# PIC32CM2532LE00100 device description
Architecture: CORTEX-M23; Family: PIC32CM; Series: PIC32CMLE00
Registers are 32-bit, read-write, reset 0x0 unless marked. A register's access mark holds for its fields unless they carry their own. Offsets are from the block's base; [hi:lo] are bit positions; {n}, {i} and the like mark numbered series.

## MPU — Memory Protection Unit
Instances: MPU 0xE000ED90
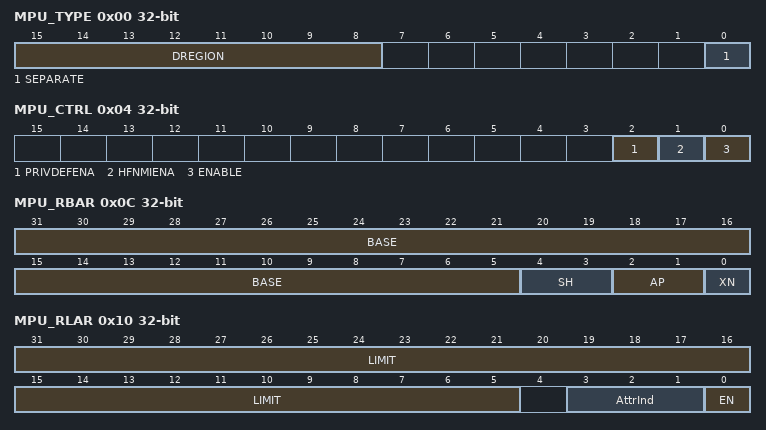
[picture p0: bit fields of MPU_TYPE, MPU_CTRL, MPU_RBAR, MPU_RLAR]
0x00 MPU_TYPE ro reset not defined
  [15:8] DREGION — Number of MPU data regions
  [0] SEPARATE — Separate instructions and data address regions
0x04 MPU_CTRL reset not defined — MPU Control Register
  [2] PRIVDEFENA — Privileged default enable
  [1] HFNMIENA — HardFault, NMI enable
  [0] ENABLE — MPU enable
0x08 MPU_RNR reset not defined — MPU Region Number Register
  [7:0] REGION — Selected region number
0x0C MPU_RBAR reset not defined — MPU Region Base Address Register
  [31:5] BASE — Base address
  [4:3] SH — Shareability
    0=NO (Non-shareable); 2=OUTER (Outer shareable); 3=INNER (Inner shareable)
  [2:1] AP — Access permissions
    0=RWPRIV (Read/write by privileged code only); 1=RWANY (Read/write by any privilege level); 2=RPRIV (Read-only by privileged code only); 3=RANY (Read-only by any privilege level)
  [0] XN — Execute Never
0x10 MPU_RLAR reset not defined — MPU Region Limit Address Register
  [31:5] LIMIT — Limit address
  [3:1] AttrInd — Attribute Index
  [0] EN — Region enable
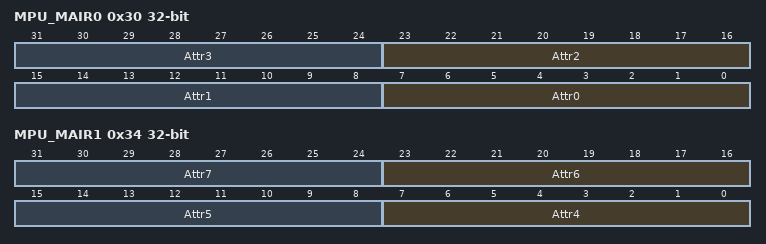
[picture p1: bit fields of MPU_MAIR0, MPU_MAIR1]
0x30 MPU_MAIR0 reset not defined — MPU Memory Attribute Indirection Register 0
  [8n+7:8n] Attr{n} (n=0..3) — Attribute of MPU region {n}
0x34 MPU_MAIR1 reset not defined — MPU Memory Attribute Indirection Register 1
  [8n-25:8n-32] Attr{n} (n=4..7) — Attribute of MPU region {n}

## NVIC — Nested Vectored Interrupt Controller
Instances: NVIC 0xE000E100
{0x0+4i} NVIC_ISER[{i}] (i=0..2) reset not defined — Interrupt Set Enable Register n
  [31:0] SETENA — Set enable
{0x80+4i} NVIC_ICER[{i}] (i=0..2) reset not defined — Interrupt Clear Enable Register n
  [31:0] CLRENA — Clear enable
{0x100+4i} NVIC_ISPR[{i}] (i=0..2) reset not defined — Interrupt Set Pending Register n
  [31:0] SETPEND — Set pending
{0x180+4i} NVIC_ICPR[{i}] (i=0..2) reset not defined — Interrupt Clear Pending Register n
  [31:0] CLRPEND — Clear pending
{0x200+4i} NVIC_IABR[{i}] (i=0..2) ro reset not defined — Interrupt Active Bit Register n
  [31:0] ACTIVE — Active state
{0x280+4i} NVIC_ITNS[{i}] (i=0..2) reset not defined — Interrupt Target Non-secure Register n
  [31:0] ITNS — Interrupt Targets Non-secure
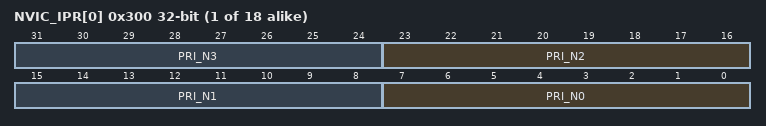
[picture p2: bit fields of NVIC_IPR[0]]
{0x300+4i} NVIC_IPR[{i}] (i=0..17) reset not defined — Interrupt Priority Register n
  [8n+7:8n] PRI_N{n} (n=0..3) — Priority of interrupt number 4n+{n}

## BOCOR_FUSES — Non-Volatile Fuses
Instances: BOCOR_FUSES 0x0080C000 in fuses
0x04 BOCOR_WORD_1 reset 0xFFE80000 — BOCOR Page Word 1
  [18:8] BOOTROM_BOOTPROT — Boot Protection
{0x0+4i} BOCOR_WORD_{i} reset 0xFFFFFFFF (i=16..19) — BOCOR Page Word {i}
  [31:0] BOOTROM_CRCKEY_{i-16} — Crc Key bits {32i-481}:{32i-512}

## OTP1_FUSES — Non-Volatile Fuses
Instances: OTP1_FUSES 0x00806000 in fuses
0x00 OTP1_WORD_0 ro reset not defined — OTP1 Page Word 0
  [10] BOOTROM_SECEN — Security Enable Fuse
0x04 OTP1_WORD_1 ro reset not defined — OTP1 Page Word 1
  [31:0] BOOTROM_NVMCRC — CRC for NVM DWORD

## OTP2_FUSES — Non-Volatile Fuses
Instances: OTP2_FUSES 0x00806008 in fuses
0x04 OTP2_WORD_1 ro reset not defined — OTP2 Page Word 1
  [15] PM_NVM3VSWDIS — 3V NVM switch disable

## SW_CALIB_FUSES — Non-Volatile Fuses
Instances: SW_CALIB_FUSES 0x00806020 in fuses
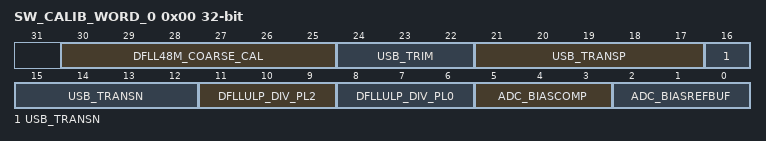
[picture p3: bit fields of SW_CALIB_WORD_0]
0x00 SW_CALIB_WORD_0 ro reset not defined — SW_CALIB Page Word 0
  [30:25] DFLL48M_COARSE_CAL — DFLL48M Coarse Calibration
  [24:22] USB_TRIM — USB pad Trim calibration
  [21:17] USB_TRANSP — USB pad Transp calibration
  [16:12] USB_TRANSN — USB pad Transn calibration
  [11:9] DFLLULP_DIV_PL2 — DFLLULP DIV at PL2
  [8:6] DFLLULP_DIV_PL0 — DFLLULP DIV at PL0
  [5:3] ADC_BIASCOMP — ADC Comparator Scaling
  [2:0] ADC_BIASREFBUF — ADC Bias Reference Buffer Scaling

## Notices in the file
Copyright (c) 2019 Microchip Technology Inc.
SPDX-License-Identifier: Apache-2.0
Licensed under the Apache License, Version 2.0 (the "License");
you may not use this file except in compliance with the License.
You may obtain a copy of the License at
http://www.apache.org/licenses/LICENSE-2.0
Unless required by applicable law or agreed to in writing, software
distributed under the License is distributed on an "AS IS" BASIS,
WITHOUT WARRANTIES OR CONDITIONS OF ANY KIND, either express or implied.
See the License for the specific language governing permissions and
limitations under the License.
